# AM13E23219 register map
Vendor: Texas Instruments; File version: 1.0
CPU: CM33 r0p1, little endian, MPU, FPU, VTOR, 4 interrupt priority bits
Registers are 32-bit, read-write, reset 0x0 unless marked. A register's access mark holds for its fields unless they carry their own. Offsets are from the block's base; [hi:lo] are bit positions; {n}, {i} and the like mark numbered series.

## ADC0RESULT — ADC_RESULT module
Base 0x4000A000
Same registers: ADC1RESULT 0x4000B000, ADC2RESULT 0x4000C000
{0x0+2i} ADCRESULT{i} 16-bit access not given (i=0..15)
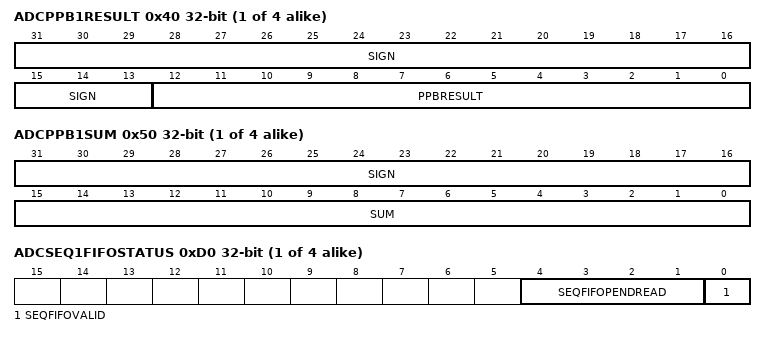
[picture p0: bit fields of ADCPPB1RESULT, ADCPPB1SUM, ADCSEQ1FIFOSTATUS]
{0x3C+4i} ADCPPB{i}RESULT ro (i=1..4) — ADC Post Processing Block {i} Result Register
  [31:13] SIGN — Sign Extended Bits
  [12:0] PPBRESULT — ADC Post Processing Block Result
{0x48+8i} ADCPPB{i}SUM ro (i=1..4) — ADC PPB {i} Final Sum Result Register
  [31:16] SIGN — Sign Extended Bits
  [15:0] SUM — Post Processing Block {i} Oversampling Sum
{0x4C+8i} ADCPPB{i}COUNT 16-bit ro (i=1..4) — ADC PPB{i} Final Conversion Count Register
  [3:0] COUNT — Post Processing Block {i} Final Count
{0xBC+4i} ADCSEQ{i}FIFORESULT access not given (i=1..4) — ADC Sequence {i} FIFO Result Register
{0xCC+4i} ADCSEQ{i}FIFOSTATUS ro (i=1..4) — ADC Sequence {i} FIFO Status
  [4:1] SEQFIFOPENDREAD — Sequencer {i} FIFO Pending reads
  [0] SEQFIFOVALID — Sequencer {i} FIFO Valid

## FLASH — FRI module
Base 0x40028000
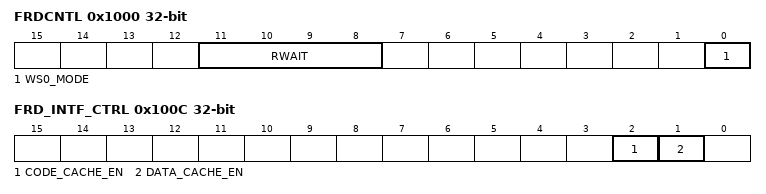
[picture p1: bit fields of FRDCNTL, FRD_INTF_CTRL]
0x1000 FRDCNTL — Flash Read Control Register
  [11:8] RWAIT — Random Read Waitstate
  [0] WS0_MODE — Wait state 0 Mode
0x100C FRD_INTF_CTRL — Flash Read Interface Control Register
  [2] CODE_CACHE_EN — Code Cache Enable
  [1] DATA_CACHE_EN — Data Cache Enable
0x1010 DTB_MUXSEL — Flash Read Interface DTB Mux select
  [1:0] DTB_MUX_SEL_FRI — FRI DTB Mux Select
0x1100 ECC_ENABLE
  [3:0] ENABLE — Enable ECC
0x1104 FECC_CTRL — ECC Control
  [1:0] ECC_TEST_EN — Enable ECC Test Logic

## MEMCFG — MEMCFG module
Base 0x4002A000
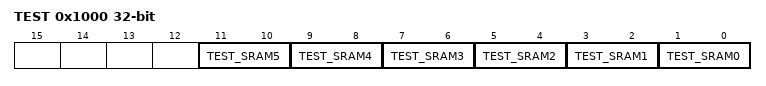
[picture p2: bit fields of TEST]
0x1000 TEST — RAM TEST Register
  [11:10] TEST_SRAM5 — Selects the different test modes for UGLXMP_2 RAM
  [9:8] TEST_SRAM4 — Selects the different test modes for UGLXMP_2 RAM
  [7:6] TEST_SRAM3 — Selects the different test modes for UGLXMP_2 RAM
  [5:4] TEST_SRAM2 — Selects the different test modes for GLXMP_1 RAM
  [3:2] TEST_SRAM1 — Selects the different test modes for GLXMP_0 RAM
  [1:0] TEST_SRAM0 — Selects the different test modes for ULL RAM
0x1010 ROM_WS_CONFIG — ROM wait state configuration
  [0] ROM_WS_ENABLE — ROM wait state 1 enable
0x1014 TMUROM_TEST
  [3:0] TMUROM_PAR_FORCE — TMUROM Parity Error Force: #br# 0xA: Error forced #br# Others: No error forced
0x1018 ECATRAM_TEST — ETHERCAT RAM TEST Register
  [3:0] ECATRAM_PAR_FORCE — ETHERCAT RAM Parity Error Force: #br# 0xA: Error forced #br# Others: No error forced

## IOMUX — IOMUX module
Base 0x400CC000
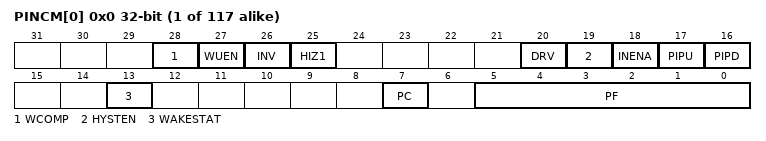
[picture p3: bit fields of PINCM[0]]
{0x0+4i} PINCM[{i}] (i=0..116) access per field — Pin Control Management Register in SECCFG region
  [28] WCOMP rw — Wakeup Compare Value bit
    0=MATCH0 (Wakeup on a match of 0); 1=MATCH1 (Wakeup on a match of 1)
  [27] WUEN rw — Wakeup Enable bit
    0=DISABLE (wakeup is disabled.); 1=ENABLE (wakeup is enabled)
  [26] INV rw — Data inversion selection
    0=DISABLE (Data inversion is disabled.); 1=ENABLE (Data inversion is enabled)
  [25] HIZ1 rw — High output value will tri-state the output when this bit is enabled
    0=DISABLE (open-drain is disabled.); 1=ENABLE (open-drain is enabled.)
  [20] DRV rw — Drive strength control selection, for HS IOCELL only
    0=DRVVAL0 (Drive setting of 0 selected); 1=DRVVAL1 (Drive setting of 1 selected)
  [19] HYSTEN rw — Hystersis Enable Control Selection
    0=DISABLE (hysteresis is disabled.); 1=ENABLE (hysteresis is enabled)
  [18] INENA rw — Input Enable Control Selection
    0=DISABLE (Input enable is disabled.); 1=ENABLE (Input enable is enabled.)
  [17] PIPU rw — Pull Up control selection
    0=DISABLE (Pull up is disabled.); 1=ENABLE (Pull up is enabled)
  [16] PIPD rw — Pull Down control selection
    0=DISABLE (Pull down is disabled.); 1=ENABLE (Pull down is enabled)
  [13] WAKESTAT ro — This has the IOPAD WAKEUP signal as status bit.
    0=DISABLE (wakeup source is NOT from this IOCELL); 1=ENABLE (wakeup source is from this IOCELL)
  [7] PC rw — Peripheral is Connected
    0=UNCONNECTED (The output of the peripheral (and its output enable) will not propagate to the IOCELL); 1=CONNECTED (The output latch of the dataflow will be transparent)
  [5:0] PF rw — P channel Function selection bits
    0=MINIMUM (Reserved as unconnected); 63=MAXIMUM (An encoding per function that can be connected to this pin.)
0x1C00 BOOTRSTPINCM
  [31:0] ENABLE — Boot reset override enable
    0=DISABLE (Bootrst out disable on pin); 1=ENABLE (Bootrst out enable on pin)
